# CY8C5267AXI_LP051 register map
File version: 0.1
CY8C52LP
Registers are 8-bit, read-write, no defined reset value unless marked. A register's access mark holds for its fields unless they carry their own. Offsets are from the block's base; lines under a group give offsets from that group; [hi:lo] are bit positions; {n}, {i} and the like mark numbered series; 'fields as' and 'values as' point back to an identical list; <NAME> marks a mode.

## Memory map
0x00000000 USBFS_1 — USBFS
0x40006471 Control_Reg_1

## USBFS_1 — USBFS
Base 0x00000000
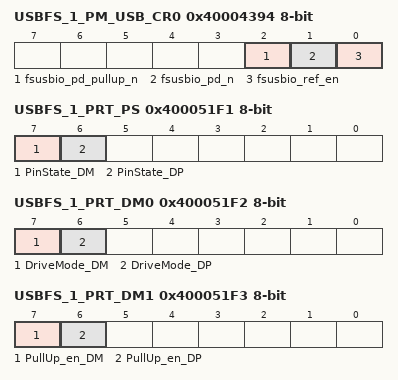
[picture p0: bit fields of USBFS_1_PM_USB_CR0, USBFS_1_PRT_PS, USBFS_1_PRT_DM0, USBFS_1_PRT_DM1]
0x40004394 USBFS_1_PM_USB_CR0 — USB Power Mode Control Register 0
  [2] fsusbio_pd_pullup_n, [1] fsusbio_pd_n, [0] fsusbio_ref_en
0x400043A5 USBFS_1_PM_ACT_CFG — Active Power Mode Configuration Register
0x400043B5 USBFS_1_PM_STBY_CFG — Standby Power Mode Configuration Register
0x400051F1 USBFS_1_PRT_PS — Port Pin State Register
  [7] PinState_DM ro, [6] PinState_DP ro
0x400051F2 USBFS_1_PRT_DM0 — Port Drive Mode Register
  [7] DriveMode_DM, [6] DriveMode_DP
0x400051F3 USBFS_1_PRT_DM1 — Port Drive Mode Register
  [7] PullUp_en_DM, [6] PullUp_en_DP
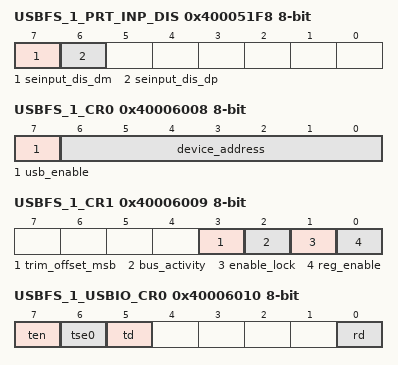
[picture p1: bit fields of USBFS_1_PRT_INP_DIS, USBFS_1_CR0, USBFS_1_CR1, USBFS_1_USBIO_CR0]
0x400051F8 USBFS_1_PRT_INP_DIS — Input buffer disable override
  [7] seinput_dis_dm, [6] seinput_dis_dp
0x40006000 USBFS_1_EP0_DR0 — bmRequestType
0x40006001 USBFS_1_EP0_DR1 — bRequest
0x40006002 USBFS_1_EP0_DR2 — wValueLo
0x40006003 USBFS_1_EP0_DR3 — wValueHi
0x40006004 USBFS_1_EP0_DR4 — wIndexLo
0x40006005 USBFS_1_EP0_DR5 — wIndexHi
0x40006006 USBFS_1_EP0_DR6 — lengthLo
0x40006007 USBFS_1_EP0_DR7 — lengthHi
0x40006008 USBFS_1_CR0 — USB Control Register 0
  [7] usb_enable, [6:0] device_address ro
0x40006009 USBFS_1_CR1 — USB Control Register 1
  [3] trim_offset_msb, [2] bus_activity, [1] enable_lock, [0] reg_enable
{0x40005FFE+0x10*i} USBFS_1_SIE_EP{i}_CR0 (i=1..8) — The Endpoint{i} Control Register
0x40006010 USBFS_1_USBIO_CR0 — USBIO Control Register 0
  [7] ten, [6] tse0, [5] td, [0] rd ro
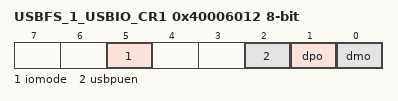
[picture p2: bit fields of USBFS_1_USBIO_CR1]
0x40006012 USBFS_1_USBIO_CR1 — USBIO Control Register 1
  [5] iomode, [2] usbpuen, [1] dpo ro, [0] dmo ro
0x4000608C USBFS_1_BUF_SIZE — Dedicated Endpoint Buffer Size Register
0x4000608E USBFS_1_EP_ACTIVE — Endpoint Active Indication Register
0x4000608F USBFS_1_EP_TYPE — Endpoint Type (IN/OUT) Indication
0x4000609D USBFS_1_USB_CLK_EN — USB Block Clock Enable Register

## Control_Reg_1
Base 0x40006471
0x00 Control_Reg_1_CONTROL_REG
